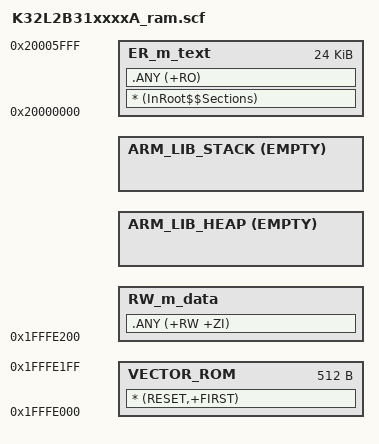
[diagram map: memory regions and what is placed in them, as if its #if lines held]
#! armcc -E
/*
** ###################################################################
**     Processors:          K32L2B31VFM0A
**                          K32L2B31VFT0A
**                          K32L2B31VLH0A
**                          K32L2B31VMP0A
**
**     Compiler:            Keil ARM C/C++ Compiler
**     Reference manual:    K32L2B3xRM, Rev.0, July 2019
**     Version:             rev. 1.0, 2019-07-30
**     Build:               b190930
**
**     Abstract:
**         Linker file for the Keil ARM C/C++ Compiler
**
**     Copyright 2016 Freescale Semiconductor, Inc.
**     Copyright 2016-2019 NXP
**     All rights reserved.
**
**     SPDX-License-Identifier: BSD-3-Clause
**
**     http:                 www.nxp.com
**     mail:                 support@nxp.com
**
** ###################################################################
*/

#define m_interrupts_start             0x1FFFE000
#define m_interrupts_size              0x00000200

#define m_data_start                   0x1FFFE200
#define m_data_size                    0x00001E00

#define m_text_start                   0x20000000
#define m_text_size                    0x00006000

/* Sizes */
#if (defined(__stack_size__))
  #define Stack_Size                   __stack_size__
#else
  #define Stack_Size                   0x0400
#endif

#if (defined(__heap_size__))
  #define Heap_Size                    __heap_size__
#else
  #define Heap_Size                    0x0400
#endif

LR_m_text m_text_start m_text_size {   ; load region size_region
  ER_m_text m_text_start m_text_size { ; load address = execution address
    * (InRoot$$Sections)
    .ANY (+RO)
  }

  RW_m_data m_data_start m_data_size-Stack_Size-Heap_Size { ; RW data
    .ANY (+RW +ZI)
  }
  ARM_LIB_HEAP +0 EMPTY Heap_Size {    ; Heap region growing up
  }
  ARM_LIB_STACK m_data_start+m_data_size EMPTY -Stack_Size { ; Stack region growing down
  }
}

LR_m_interrupts m_interrupts_start m_interrupts_size {
  VECTOR_ROM m_interrupts_start m_interrupts_size { ; load address = execution address
    * (RESET,+FIRST)
  }
}

